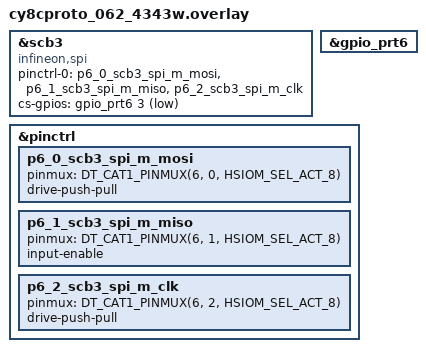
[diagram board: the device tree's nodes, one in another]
/*
 * SPDX-FileCopyrightText: Copyright The Zephyr Project Contributors
 *
 * SPDX-License-Identifier: Apache-2.0
 */

#define SPI_LOOPBACK_SLOW_HZ 2000000
#define SPI_LOOPBACK_FAST_HZ 3000000

spi_loopback: &scb3 {
	compatible = "infineon,spi";
	status = "okay";

	pinctrl-0 = <&p6_0_scb3_spi_m_mosi &p6_1_scb3_spi_m_miso &p6_2_scb3_spi_m_clk>;
	pinctrl-names = "default";
	cs-gpios = <&gpio_prt6 3 GPIO_ACTIVE_LOW>;
};

&gpio_prt6 {
	status = "okay";
};

&pinctrl {
	/* Configure pin control bias mode for SPI pins */
	p6_0_scb3_spi_m_mosi: p6_0_scb3_spi_m_mosi {
		pinmux = <DT_CAT1_PINMUX(6, 0, HSIOM_SEL_ACT_8)>;
		drive-push-pull;
	};

	p6_1_scb3_spi_m_miso: p6_1_scb3_spi_m_miso {
		pinmux = <DT_CAT1_PINMUX(6, 1, HSIOM_SEL_ACT_8)>;
		input-enable;
	};

	p6_2_scb3_spi_m_clk: p6_2_scb3_spi_m_clk {
		pinmux = <DT_CAT1_PINMUX(6, 2, HSIOM_SEL_ACT_8)>;
		drive-push-pull;
	};
};

#include "../spi-loopback.dtsi"
